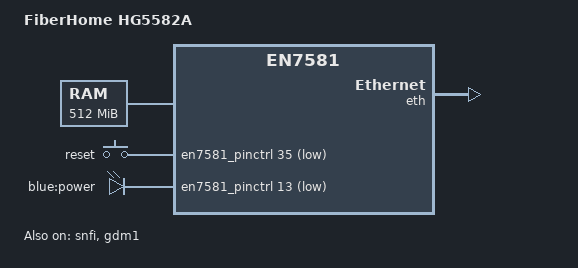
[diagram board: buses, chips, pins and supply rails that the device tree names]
// SPDX-License-Identifier: (GPL-2.0-only OR BSD-2-Clause)
/dts-v1/;

/* BL2 and TF-A reserve the first 2 MiB of DRAM. */
/memreserve/ 0x80000000 0x200000;

#include <dt-bindings/gpio/gpio.h>
#include <dt-bindings/input/input.h>
#include "en7581.dtsi"

/ {
	model = "FiberHome HG5582A";
	compatible = "fiberhome,hg5582a", "airoha,an7581", "airoha,en7581";

	aliases {
		serial0 = &uart1;
	};

	chosen {
		stdout-path = "serial0:115200n8";
	};

	memory@80000000 {
		device_type = "memory";
		reg = <0x0 0x80000000 0x0 0x20000000>;
	};

	keys {
		compatible = "gpio-keys";

		key-reset {
			label = "reset";
			linux,code = <KEY_RESTART>;
			gpios = <&en7581_pinctrl 35 GPIO_ACTIVE_LOW>;
		};
	};

	leds {
		compatible = "gpio-leds";

		led-power {
			label = "blue:power";
			gpios = <&en7581_pinctrl 13 GPIO_ACTIVE_LOW>;
			default-state = "keep";
		};
	};
};

&en7581_pinctrl {
	gpio-ranges = <&en7581_pinctrl 0 13 50>;
};

/* 本机 NAND 挂在 SNFI(串口 NAND 接口) 上，不是并口 NFI */
&snfi {
	status = "okay";
};

&spi_nand {
	compatible = "winbond,w29n02kv", "spi-nand";

	partitions {
		compatible = "fixed-partitions";
		#address-cells = <1>;
		#size-cells = <1>;

		partition@0 {
			label = "bl2";
			/* BootROM 读首块 0x800 处的 BL2 FIP */
			reg = <0x00000000 0x00020000>;
		};

		partition@20000 {
			label = "ubi";
			reg = <0x00020000 0x00000000>;
		};
	};
};

&eth {
	status = "okay";
};

&gdm1 {
	status = "okay";
};
